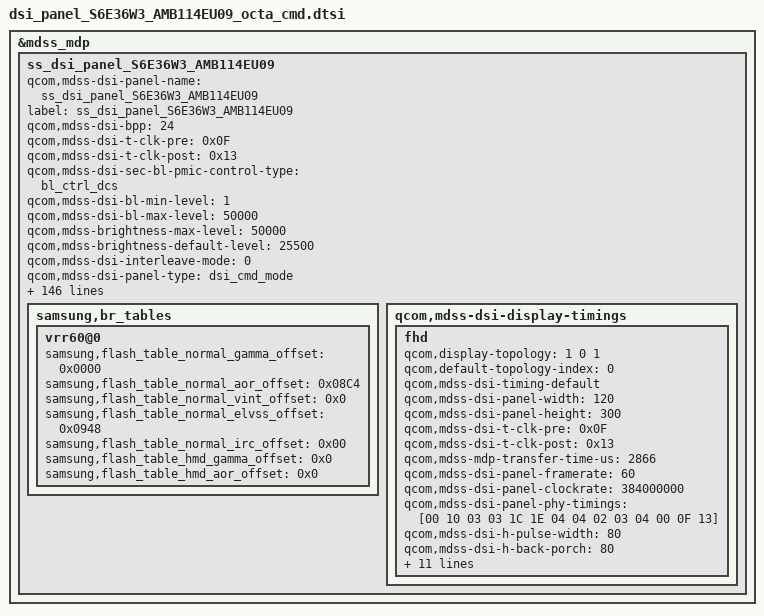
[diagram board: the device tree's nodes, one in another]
/* Copyright (c) 2013-2014, The Linux Foundation. All rights reserved.
 *
 * This program is free software; you can redistribute it and/or modify
 * it under the terms of the GNU General Public License version 2 and
 * only version 2 as published by the Free Software Foundation.
 *
 * This program is distributed in the hope that it will be useful,
 * but WITHOUT ANY WARRANTY; without even the implied warranty of
 * MERCHANTABILITY or FITNESS FOR A PARTICULAR PURPOSE.  See the
 * GNU General Public License for more details.
 */

/*---------------------------------------------------------------------------
 * This file is autogenerated file using gcdb parser. Please do not edit it.
 * Update input XML file to add a new entry or update variable in this file
 * VERSION = "1.0"
 *---------------------------------------------------------------------------*/
&mdss_mdp {
	ss_dsi_panel_S6E36W3_AMB114EU09: ss_dsi_panel_S6E36W3_AMB114EU09 {
		qcom,mdss-dsi-panel-name = "ss_dsi_panel_S6E36W3_AMB114EU09";
		label = "ss_dsi_panel_S6E36W3_AMB114EU09";
		qcom,mdss-dsi-bpp = <24>;
		qcom,mdss-dsi-t-clk-pre = <0x0F>;
		qcom,mdss-dsi-t-clk-post = <0x13>;
		qcom,mdss-dsi-sec-bl-pmic-control-type = "bl_ctrl_dcs";

		qcom,mdss-dsi-bl-min-level = <1>;
		qcom,mdss-dsi-bl-max-level = <50000>;
		qcom,mdss-brightness-max-level = <50000>;
		qcom,mdss-brightness-default-level = <25500>;

		qcom,mdss-dsi-interleave-mode = <0>;
		qcom,mdss-dsi-panel-type = "dsi_cmd_mode";

		qcom,mdss-dsi-te-check-enable;
		qcom,mdss-dsi-te-using-te-pin;
		qcom,mdss-dsi-te-pin-select = <1>;

		qcom,mdss-dsi-te-dcs-command = <1>;
		qcom,mdss-dsi-wr-mem-start = <0x2C>;
		qcom,mdss-dsi-wr-mem-continue = <0x3C>;

		/* CMD mode panel doesn't need below stuff */
		qcom,mdss-dsi-h-sync-pulse= <0>;
		/*qcom,mdss-dsi-hfp-power-mode=*/
		/*qcom,mdss-dsi-hbp-power-mode=*/
		/*qcom,mdss-dsi-hsa-power-mode=*/
		/*qcom,mdss-dsi-last-line-interleave=*/
		qcom,mdss-dsi-bllp-eof-power-mode;
		qcom,mdss-dsi-bllp-power-mode;
		qcom,mdss-dsi-traffic-mode= "burst_mode";

		qcom,mdss-dsi-pixel-packing = "loose";

		qcom,mdss-dsi-virtual-channel-id = <0>;
		qcom,mdss-dsi-color-order = "rgb_swap_rgb";
		qcom,mdss-dsi-lane-0-state;
		samsung,num_of_data_lanes = <1>;

		qcom,mdss-dsi-stream = <0>;
		qcom,mdss-dsi-mdp-trigger = "none";
		qcom,mdss-dsi-dma-trigger = "trigger_sw";

		qcom,mdss-dsi-off-command-state = "dsi_hs_mode";

		qcom,mdss-pan-physical-width-dimension = <10>;	/* 9.93mm */
		qcom,mdss-pan-physical-height-dimension = <25>;	/* 25.11mm */

		qcom,mdss-dsi-reset-sequence = <1 5>;

		qcom,mdss-dsi-rx-eot-ignore;
		qcom,mdss-dsi-tx-eot-append;
		qcom,ulps-enabled;

		/* HDR Setting */
		qcom,mdss-dsi-panel-hdr-enabled;
		qcom,mdss-dsi-panel-hdr-color-primaries = <15635 16450 34000 16000 13250 34500 7500 3000>;
		qcom,mdss-dsi-panel-peak-brightness = <4000000>;
		qcom,mdss-dsi-panel-average-brightness = <1200000>;
		qcom,mdss-dsi-panel-blackness-level = <5>;		

		/*qcom,mdss-dsi-panel-status-command=*/
		/*qcom,mdss-dsi-panel-status-command-mode="dsi_lp_mode";*/
		/*qcom,esd-check-enabled;*/
		qcom,mdss-dsi-panel-status-check-mode="irq_check";
		/*qcom,mdss-dsi-panel-status-value = <1>;*/
		qcom,mdss-dsi-panel-status-irq-trigger1="falling";

		/*qcom,dynamic-mode-switch-enabled;*/
		/*qcom,dynamic-mode-switch-type = "dynamic-resolution-switch-immediate";*/
		/*qcom,dynamic-mode-switch-enabled*/
		/*qcom,video-to-cmd-mode-switch-commands=*/
		/*qcom,cmd-to-video-mode-switch-commands=*/

		/*qcom,adjust-timer-wakeup-ms = <1>;*/

/*
 * ************************************************************************************************************************************
 *
 *
 *			for log debug
 *
 *
 * ************************************************************************************************************************************
 */
		samsung,ldi_log_disable_tx_cmds_revA = [
			29 01 00 00 00 00 02 F2 00			/* DDI Log Disable */
		];

		samsung,ldi_log_enable_tx_cmds_revA = [
			29 01 00 00 00 00 02 F2 13			/* DDI Log Enable */
		];

		samsung,ldi_log_rx_cmds_revA		= [06 01 00 00 00 00 01 9C 80 00];

/*
 * ************************************************************************************************************************************
 *
 *
 *			Below  parameters are samsung dependent thigs
 *
 *
 * ************************************************************************************************************************************
 */
		samsung,support_panel_max = <1>;
/*		samsung,panel-lpm-enable;*/
		samsung,support_factory_panel_swap;
		samsung,support_irc;
/*		samsung,support_pac;*/
/*		samsung,support_poc_driver;*/
/*		samsung,support_gpara;*/
		samsung,multi_to_one_support;
		samsung,support_window_color;
		/*
		* ************************************************************************************************************************
		*  Tx
		* ************************************************************************************************************************
		*/

		samsung,display_on_tx_cmds_revA = [
			05 01 00 00 00 00 01 29
		];

		samsung,display_off_tx_cmds_revA = [
			05 01 00 00 00 00 01 28
		];

		samsung,level1_key_enable_tx_cmds_revA = [
			29 01 00 00 00 00 03 F0 5A 5A
		];
		samsung,level1_key_disable_tx_cmds_revA = [
			29 01 00 00 00 00 03 F0 A5 A5
		];
		samsung,level2_key_enable_tx_cmds_revA = [
			29 00 00 00 00 00 03 F0 5A 5A
			29 01 00 00 00 00 03 FC 5A 5A
		];
		samsung,level2_key_disable_tx_cmds_revA = [
			29 00 00 00 00 00 03 F0 A5 A5
			29 01 00 00 00 00 03 FC A5 A5
		];

		/* BRIGHTNESS_MAX_PACKET = 50 */
		samsung,brightness_tx_cmds_revA = [
			39 01 00 00 00 00 01 00
			39 01 00 00 00 00 01 00
			39 01 00 00 00 00 01 00
			39 01 00 00 00 00 01 00
			39 01 00 00 00 00 01 00
			39 01 00 00 00 00 01 00
			39 01 00 00 00 00 01 00
			39 01 00 00 00 00 01 00
			39 01 00 00 00 00 01 00
			39 01 00 00 00 00 01 00
			39 01 00 00 00 00 01 00
			39 01 00 00 00 00 01 00
			39 01 00 00 00 00 01 00
			39 01 00 00 00 00 01 00
			39 01 00 00 00 00 01 00
			39 01 00 00 00 00 01 00
			39 01 00 00 00 00 01 00
			39 01 00 00 00 00 01 00
			39 01 00 00 00 00 01 00
			39 01 00 00 00 00 01 00
			39 01 00 00 00 00 01 00
			39 01 00 00 00 00 01 00
			39 01 00 00 00 00 01 00
			39 01 00 00 00 00 01 00
			39 01 00 00 00 00 01 00
			39 01 00 00 00 00 01 00
			39 01 00 00 00 00 01 00
			39 01 00 00 00 00 01 00
			39 01 00 00 00 00 01 00
			39 01 00 00 00 00 01 00
			39 01 00 00 00 00 01 00
			39 01 00 00 00 00 01 00
			39 01 00 00 00 00 01 00
			39 01 00 00 00 00 01 00
			39 01 00 00 00 00 01 00
			39 01 00 00 00 00 01 00
			39 01 00 00 00 00 01 00
			39 01 00 00 00 00 01 00
			39 01 00 00 00 00 01 00
			39 01 00 00 00 00 01 00
			39 01 00 00 00 00 01 00
			39 01 00 00 00 00 01 00
			39 01 00 00 00 00 01 00
			39 01 00 00 00 00 01 00
			39 01 00 00 00 00 01 00
			39 01 00 00 00 00 01 00
			39 01 00 00 00 00 01 00
			39 01 00 00 00 00 01 00
			39 01 00 00 00 00 01 00
			39 01 00 00 00 00 01 00
		];

		samsung,mdnie_tx_cmds_revA = [
			39 01 00 00 00 00 00 00 00
		];

		samsung,packet_size_tx_cmds_revA = [
			37 01 00 00 00 00 02 07 00
		];

		/*
		 * First parameters can be changed
		 * by function of samsung_nv_read()
		 * because of that means offset of
		 * read position
		 */
		samsung,reg_read_pos_tx_cmds_revA = [
			15 01 00 00 00 00 02 B0 00
		];

		/*
		 * ************************************************************************************************************************
		 *	 06 01 00 00 00 00 01 c8 07 21
		 *	READ 0xC8 SIZE 0x07 OFFSET 0x21
		 * ************************************************************************************************************************
		 */
		samsung,smart_dimming_mtp_rx_cmds_revA = [ 06 01 00 00 00 00 01 c8 24 00]; /* read C8 36para */
		/* the last byte in all read commands will represent READ LENGH */
		samsung,manufacture_id0_rx_cmds_revA = [ 06 01 00 00 00 00 01 da 01 00];
		samsung,manufacture_id1_rx_cmds_revA = [ 06 01 00 00 00 00 01 db 01 00];
		samsung,manufacture_id2_rx_cmds_revA = [ 06 01 00 00 00 00 01 dc 01 00];

		samsung,manufacture_date_rx_cmds_revA = [ 06 01 00 00 00 00 01 A1 04 04];	/* read A1 5~8th */
		samsung,ddi_id_rx_cmds_revA = [ 06 01 00 00 00 00 01 d6 05 00];	/* read D6 1~5th */
		samsung,cell_id_rx_cmds_revA = [ 06 01 00 00 00 00 01 A1 07 04]; /* read A1 5th~11th */
		samsung,octa_id_rx_cmds_revA = [06 01 00 00 00 00 01 C9 14 01];  // read C9 2th~21th
		samsung,mtp_read_sysfs_rx_cmds_revA = [ 06 01 00 00 00 00 01 01 01 01];
		samsung,mtp_write_sysfs_tx_cmds_revA = [
			29 01 00 00 00 00 0E 00
						00 00 00 00 00 00 00 00 00 00
						00 00 00
		];
		samsung,mdnie_read_rx_cmds_revA	= [ 06 01 00 00 00 00 01 A1 04 00];

		samsung,ldi_debug0_rx_cmds_revA		= [06 01 00 00 00 00 01 0A 01 00];
		samsung,ldi_debug1_rx_cmds_revA		= [06 01 00 00 00 00 01 ED 01 00];
	/*	samsung,ldi_debug2_rx_cmds_revA		= [06 01 00 00 00 00 01 EE 01 00]; */
	/*	samsung,ldi_debug3_rx_cmds_revA		= [06 01 00 00 00 00 01 0E 01 00]; */
	/*	samsung,ldi_debug4_rx_cmds_revA		= [06 01 00 00 00 00 01 05 01 00]; */
	/*	samsung,ldi_debug5_rx_cmds_revA		= [06 01 00 00 00 00 01 0F 01 00]; */

		/* *************************************************************
		 *  SELF DISPLAY
		 * *************************************************************
		 */
		samsung,support_self_display;
		ss,self_display = <&self_display_6W3_dtsi>;
		/*
		 * ************************************************************************************************************************
		 *	 COMMON CMD LIST
		 * ************************************************************************************************************************
		 */

		samsung,gamma_tx_cmds_revA = [
		29 01 00 00 00 00 23 CA				/* 1) Gamma 2.2 Setting */
						07 00 00 00			/* V255 R,G,B */
						80 80 80			/* V203 R,G,B */
						80 80 80			/* V151 R,G,B */
						80 80 80			/* V87 R,G,B */
						80 80 80			/* V51 R,G,B */
						80 80 80			/* V35 R,G,B */
						80 80 80			/* V23 R,G,B */
						80 80 80			/* V11 R,G,B */
						80 80 80			/*  V7 R,G,B */
						80 80 80			/*  V1 R,G,B */
						00 00 00			/*  V0 R,G,B & VT G,R,B*/

			29 01 00 00 00 00 02 F7 03	/* Gamma, LTPS(AID) update */

			29 01 00 00 00 00 3C		/* dummy for single transmission more 100ns delay */
			00 00 00 00 00 00 00 00 00 00
			00 00 00 00 00 00 00 00 00 00
			00 00 00 00 00 00 00 00 00 00
			00 00 00 00 00 00 00 00 00 00
			00 00 00 00 00 00 00 00 00 00
			00 00 00 00 00 00 00 00 00 00
		];

		/*
		* ************************************************************************************************************************
		*  HBM
		* ************************************************************************************************************************
		*/

		samsung,enter_hbm_ce_lux = <10000>;
		samsung,hbm_etc_tx_cmds_revA = [
			29 00 00 00 00 00 03 F0 5A 5A		/* TEST KEY Enable */
			29 00 00 00 00 00 04 B5 19 DC 0A	/* MPS/ELVSS Setting */ /* TBD */
			29 00 00 00 00 00 02 B3 21			/* HBM ACL ON */
			29 00 00 00 00 00 02 55 00			/* ACL OFF */
			29 00 00 00 00 00 04 B1 00 20 20	/* AID Setting 1000nit*/
			29 00 00 00 00 00 02 53 C0			/* HBM ON */
			29 00 00 00 00 00 02 F7 03			/* Gamma & AID update */
			29 01 00 00 00 00 03 F0 5A 5A		/* TEST KEY Disable */
		];

		samsung,hbm_off_tx_cmds_revA = [
			29 01 00 00 00 00 02 53 00			/* HBM off */
		];

		/* *************************************************************
		 * TEST MODE
		 * **************************************************************
		 */
		samsung,mcd_on_tx_cmds_revA = [
			29 01 00 00 00 00 03 F0 5A 5A
			29 01 00 00 64 00 49 CB
				20 01 01 01 40 01 01 23
				34 50 12 00 00 09 02 00
				00 00 00 00 00 6D 60 00
				00 00 00 07 00 00 00 00
				00 02 C4 02 09 01 02 0C
				0C 0C 0C 0C 0C D4 0F 10
				0D 84 05 C2 0B 0B 0B EB
				EB CB D3 D4 CF 50 CD C4
				C5 E2 EB 0B 0B 0B 0B 0B

			29 01 00 00 00 00 02 F7 02
			29 01 00 00 00 00 08 F2
				34 15 2C 60 30 96 00

			29 01 00 00 00 00 03 F0 A5 A5
		];

		samsung,mcd_off_tx_cmds_revA = [
			29 01 00 00 00 00 03 F0 5A 5A
			29 01 00 00 64 00 49 CB
				20 01 01 01 40 01 01 33
				34 50 12 00 00 09 04 00
				00 00 00 00 00 6D 60 00
				00 00 00 07 00 00 00 00
				00 02 C4 00 00 01 02 0C
				0C 0C 0C 0C 0C D4 0F 10
				0D 84 05 C2 16 17 18 F9
				FA DB D3 D4 CF 50 CD C4
				C5 E2 F6 17 18 19 1A 1B

			29 01 00 00 00 00 02 F7 02
			29 01 00 00 00 00 08 F2
				34 15 2C 60 30 96 2B
			
			29 01 00 00 00 00 03 F0 A5 A5
		];
		
		/*
		 * ************************************************************************************************************************
		 * ACL command list and mappings
		 * ************************************************************************************************************************
		 */

		samsung,acl_on_tx_cmds_revA = [
			29 01 00 00 00 00 02 55 02	/* ACL ON */
		];


		samsung,acl_off_tx_cmds_revA = [
			29 01 00 00 00 00 02 55 00	 /* ACL OFF */
		];

		/* bl_level , Index in acl command list */
		samsung,acl_map_table_revA =  <
			10	1		11	1
			12	1		13	1		14	1		15	1		16	1
			17	1		19	1		20	1		21	1		22	1
			24	1		25	1		27	1		29	1		30	1
			32	1		34	1		37	1		39	1		41	1
			44	1		47	1		50	1		53	1		56	1
			60	1		64	1		68	1		72	1		77	1
			82	1		87	1		93	1		98	1		105	1
			111	1		119	1		126	1		134	1		143	1
			152	1		162	1		172	1		183	1		195	1
			207	1		220	1		234	1		249	1		265	1
			282	1		300	1		316	1		333	1		350	1
			357	1		365	1		372	1		380	1		387	1
			395	1		403	1		412	1		420	1
		>;
		/*
		* ************************************************************************************************************************
		* ELVSS command list and mappings
		* ************************************************************************************************************************
		*/

		/* TSET MPS_CON ELVSS_Dim_offset */
		samsung,elvss_tx_cmds_revA = [
			29 01 00 00 00 00 04 B5 19 DC 0A /* 0  420CD ~ 395CD */
			29 01 00 00 00 00 04 B5 19 DC 0B /* 1  387CD ~ 333CD */
			29 01 00 00 00 00 04 B5 19 DC 0C /* 2  316CD ~ 282CD */
			29 01 00 00 00 00 04 B5 19 DC 0D /* 3  265CD ~ 249CD*/
			29 01 00 00 00 00 04 B5 19 DC 0E /* 4  234CD ~ 152CD*/
			29 01 00 00 00 00 04 B5 19 DC 0F /* 5  143CD ~ 105CD */
			29 01 00 00 00 00 04 B5 19 DC 10 /* 6  98CD ~ 10CD */
		];

		/* bl_level, Index in elvss command list */
		samsung,smart_acl_elvss_map_table_revA = <
			10	6	11	6
			12	6	13	6	14	6	15	6	16	6
			17	6	19	6	20	6	21	6	22	6
			24	6	25	6	27	6	29	6	30	6
			32	6	34	6	37	6	39	6	41	6
			44	6	47	6	50	6	53	6	56	6
			60	6	64	6	68	6	72	6	77	6
			82	6	87	6	93	6	98	6	105	5
			111	5	119	5	126	5	134	5	143	5
			152	4	162	4	172	4	183	4	195	4
			207	4	220	4	234	4	249	3	265	3
			282	2	300	2	316	2	333	1	350	1
			357	1	365	1	372	1	380	1	387	1
			395	1	403	1	412	0	420	0
		>;
		/* *************************************************************
		 * AID command list and mappings
		 * **************************************************************
		 */
		/* Original aid table for all steps. */
		samsung,aid_subdivision_tx_cmds_revA = [
			29 01 00 00 00 00 03 B1	01 23	/*	10 	*/
			29 01 00 00 00 00 03 B1	01 21	/*	11 	*/
			29 01 00 00 00 00 03 B1	01 1C	/*	12 	*/
			29 01 00 00 00 00 03 B1	01 1C	/*	13 	*/
			29 01 00 00 00 00 03 B1	01 1A	/*	14 	*/
			29 01 00 00 00 00 03 B1	01 19	/*	15 	*/
			29 01 00 00 00 00 03 B1	01 13	/*	16 	*/
			29 01 00 00 00 00 03 B1	01 12	/*	17 	*/
			29 01 00 00 00 00 03 B1	01 0B	/*	19 	*/
			29 01 00 00 00 00 03 B1	01 0A	/*	20 	*/
			29 01 00 00 00 00 03 B1	01 05	/*	21 	*/
			29 01 00 00 00 00 03 B1	01 03	/*	22 	*/
			29 01 00 00 00 00 03 B1	00 FC	/*	24 	*/
			29 01 00 00 00 00 03 B1	00 FB	/*	25 	*/
			29 01 00 00 00 00 03 B1	00 F4	/*	27 	*/
			29 01 00 00 00 00 03 B1	00 F1	/*	29 	*/
			29 01 00 00 00 00 03 B1	00 EC	/*	30 	*/
			29 01 00 00 00 00 03 B1	00 E9	/*	32 	*/
			29 01 00 00 00 00 03 B1	00 E2	/*	34 	*/
			29 01 00 00 00 00 03 B1	00 DA	/*	37 	*/
			29 01 00 00 00 00 03 B1	00 D3	/*	39 	*/
			29 01 00 00 00 00 03 B1	00 CF	/*	41 	*/
			29 01 00 00 00 00 03 B1	00 C8	/*	44 	*/
			29 01 00 00 00 00 03 B1	00 BE	/*	47 	*/
			29 01 00 00 00 00 03 B1	00 B4	/*	50 	*/
			29 01 00 00 00 00 03 B1	00 AC	/*	53 	*/
			29 01 00 00 00 00 03 B1	00 A4	/*	56 	*/
			29 01 00 00 00 00 03 B1	00 9A	/*	60 	*/
			29 01 00 00 00 00 03 B1	00 8B	/*	64 	*/
			29 01 00 00 00 00 03 B1	00 84	/*	68 	*/
			29 01 00 00 00 00 03 B1	00 84	/*	72 	*/
			29 01 00 00 00 00 03 B1	00 84	/*	77 	*/
			29 01 00 00 00 00 03 B1	00 84	/*	82 	*/
			29 01 00 00 00 00 03 B1	00 84	/*	87 	*/
			29 01 00 00 00 00 03 B1	00 84	/*	93 	*/
			29 01 00 00 00 00 03 B1	00 84	/*	98 	*/
			29 01 00 00 00 00 03 B1	00 84	/*	105 	*/
			29 01 00 00 00 00 03 B1	00 84	/*	111 	*/
			29 01 00 00 00 00 03 B1	00 84	/*	119 	*/
			29 01 00 00 00 00 03 B1	00 84	/*	126 	*/
			29 01 00 00 00 00 03 B1	00 84	/*	134 	*/
			29 01 00 00 00 00 03 B1	00 84	/*	143 	*/
			29 01 00 00 00 00 03 B1	00 84	/*	152 	*/
			29 01 00 00 00 00 03 B1	00 84	/*	162 	*/
			29 01 00 00 00 00 03 B1	00 84	/*	172 	*/
			29 01 00 00 00 00 03 B1	00 82	/*	183 	*/
			29 01 00 00 00 00 03 B1	00 73	/*	195 	*/
			29 01 00 00 00 00 03 B1	00 63	/*	207 	*/
			29 01 00 00 00 00 03 B1	00 53	/*	220 	*/
			29 01 00 00 00 00 03 B1	00 43	/*	234 	*/
			29 01 00 00 00 00 03 B1	00 3D	/*	249 	*/
			29 01 00 00 00 00 03 B1	00 3D	/*	265 	*/
			29 01 00 00 00 00 03 B1	00 3D	/*	282 	*/
			29 01 00 00 00 00 03 B1	00 3D	/*	300 	*/
			29 01 00 00 00 00 03 B1	00 3D	/*	316 	*/
			29 01 00 00 00 00 03 B1	00 3D	/*	333 	*/
			29 01 00 00 00 00 03 B1	00 3D	/*	350 	*/
			29 01 00 00 00 00 03 B1	00 3D	/*	357 	*/
			29 01 00 00 00 00 03 B1	00 3B	/*	365 	*/
			29 01 00 00 00 00 03 B1	00 34	/*	372 	*/
			29 01 00 00 00 00 03 B1	00 2C	/*	380 	*/
			29 01 00 00 00 00 03 B1	00 27	/*	387 	*/
			29 01 00 00 00 00 03 B1	00 23	/*	395 	*/
			29 01 00 00 00 00 03 B1	00 20	/*	403 	*/
			29 01 00 00 00 00 03 B1	00 20	/*	412 	*/
			29 01 00 00 00 00 03 B1	00 20	/*	420 	*/
		];
		/*
		 * ************************************************************************************************************************
		 * candela to index mappings
		 * ************************************************************************************************************************
		 */
		samsung,candela_map_table_revA = <
		/* <scaled idx> <idx>  <from>  <end> <cd> <interpolation cd>*/
			0	0	4099	10
			1	4100	4299	11
			2	4300	4499	12
			3	4500	4699	13
			4	4700	4899	14
			5	4900	5099	15
			6	5100	5299	16
			7	5300	5499	17
			8	5500	5699	19
			9	5700	5799	20
			10	5800	5999	21
			11	6000	6199	22
			12	6200	6399	24
			13	6400	6599	25
			14	6600	6799	27
			15	6800	6999	29
			16	7000	7099	30
			17	7100	7299	32
			18	7300	7499	34
			19	7500	7699	37
			20	7700	7899	39
			21	7900	8099	41
			22	8100	8299	44
			23	8300	8499	47
			24	8500	8699	50
			25	8700	8899	53
			26	8900	9099	56
			27	9100	9299	60
			28	9300	9499	64
			29	9500	9699	68
			30	9700	9899	72
			31	9900	10099	77
			32	10100	10299	82
			33	10300	10499	87
			34	10500	10699	93
			35	10700	10899	98
			36	10900	11099	105
			37	11100	11299	111
			38	11300	11499	119
			39	11500	11699	126
			40	11700	11899	134
			41	11900	12099	143
			42	12100	12399	152
			43	12400	12699	162
			44	12700	12799	172
			45	12800	12899	183
			46	12900	13599	195
			47	13600	14299	207
			48	14300	14999	220
			49	15000	15799	234
			50	15800	16599	249
			51	16600	17499	265
			52	17500	18399	282
			53	18400	19399	300
			54	19400	20199	316
			55	20200	21099	333
			56	21100	21999	350
			57	22000	22399	357
			58	22400	22799	365
			59	22800	23099	372
			60	23100	23499	380
			61	23500	23899	387
			62	23900	24299	395
			63	24300	24699	403
			64	24700	25099	412
			65	25100	25500	420
		>;
		/* GRAY/ BRONZE use same table_revA 50/183/300/420/670/1000 */
		samsung,multi_to_one_candela_map_table_revA = <
		/* <idx>  <from>  <end> <cd> */
			24	0	2399	50
			45	2400	4899	183
			53	4900	7299	300
			65	7300	9599	420
 		>;
		samsung,hbm_candela_map_table_revA = <
			0	9600	11999	670	5
			1	12000	50000	1000	6
		>;

		/* WHITE uses table_revK 32/119/207/282/440/666 */
		samsung,multi_to_one_candela_map_table_revK = <
		/* <idx>  <from>  <end> <cd> */
			17	0	2399	32			/* BLOOMX_TODO : need to modify proper idx & cd values for WHITE */
			38	2400	4899	119
			47	4900	7299	207
			52	7300	9599	282
 		>;

		samsung,hbm_candela_map_table_revK = <
			0	9600	11999	440	5		/* BLOOMX_TODO : need to modify proper just cd value for WHITE */
			1	12000	50000	666	6
		>;

		/*
		* ************************************************************************************************************************
		*  VINT
		* ************************************************************************************************************************
		*/

		/*
		* ************************************************************************************************************************
		* Self Display Operation (ENABLE)
		* ************************************************************************************************************************
		*/

		samsung,self_dispaly_on_revA = [
			29 01 00 00 00 00 03 F0 5A 5A	/* TEST KEY Enable */
			29 01 00 00 00 00 07 76
								08 10 84 38 08
								AC
			29 01 00 00 00 00 03 F0 A5 A5	/* TEST KEY Disable */
		];

		samsung,self_dispaly_off_revA = [
			29 01 00 00 00 00 03 F0 5A 5A	/* TEST KEY Enable */
			29 01 00 00 00 00 04 76
								08 10 00
			29 01 00 00 00 00 03 F0 A5 A5	/* TEST KEY Disable */
		];

		/*
		* ************************************************************************************************************************
		* Self Display Operation (SELF MASK)
		* ************************************************************************************************************************
		*/

		samsung,self_mask_mem_setting_revA = [
			29 01 00 00 00 00 03 F0 5A 5A	/* TEST KEY Enable */
			29 01 00 00 00 00 02 7A 00		/* SM_MASK_EN(0)   */
			29 01 00 00 00 00 02 75 10		/* MA_SEL(1), IC_SEL, VI_SEL, DC_SEL, AC_SEL */
			/* image data (4C,5C) ... */
			29 01 00 00 00 00 03 F0 A5 A5	/* TEST KEY Disable */
		];

		samsung,self_mask_on_revA = [
			29 01 00 00 00 00 03 F0 5A 5A	/* TEST KEY Enable */
			29 01 00 00 00 00 10 7A
								01 00 00 00 3B
								08 70 08 AB 08
								10 00 00 00 00
			29 01 00 00 00 00 03 F0 A5 A5	/* TEST KEY Disable */
		];

		samsung,self_mask_off_revA = [
			29 01 00 00 00 00 03 F0 5A 5A	/* TEST KEY Enable  */
			29 01 00 00 00 00 02 7A 00		/* SM_MASK_EN(0)	*/
			29 01 00 00 00 00 03 F0 A5 A5	/* TEST KEY Disable */
		];

#if 0
		/*
		* ************************************************************************************************************************
		* Self Display Operation (SELF MOVE)
		* ************************************************************************************************************************
		*/

		samsung,self_move_small_jump_on_revA = [
			29 01 00 00 00 00 03 F0 5A 5A	/* TEST KEY Enable */
			29 01 00 00 00 00 02 B0 33
			29 01 00 00 00 00 62 7D
								00 00 00 00 00
								00 00 33 33 33
								33 33 33 33 33
								33 33 33 33 33
								33 33 33 33 33
								33 33 33 33 33
								33 33 33 33 33
								33 33 33 33 33
								33 33 33 33 33
								33 33 33 33 33
								33 33 33 33 33
								33 33 33 33 33
								33 33 33 33 33
								33 11 11 11 11
								11 11 11 11 11
								11 11 11 11 11
								11 11 11 11 11
								11 11 11 11 11
								11 11 11 11 11
								11 90
			29 01 00 00 00 00 03 F0 A5 A5	/* TEST KEY Disable */
		];

		samsung,self_move_mid_big_jump_on_revA = [
			29 01 00 00 00 00 03 F0 5A 5A	/* TEST KEY Enable */
		/*	29 01 00 00 00 00 02 B0 33 */
			29 01 00 00 00 00 62 7D
								00 00 00 00 00
								00 00 33 33 33
								33 33 33 33 33
								33 33 33 33 33
								33 33 33 33 33
								33 33 33 33 33
								33 33 33 33 33
								33 33 33 33 33
								33 33 33 33 33
								33 33 33 33 33
								33 33 33 33 33
								33 33 33 33 33
								33 33 33 33 33
								33 11 11 11 11
								11 11 11 11 11
								11 11 11 11 11
								11 11 11 11 11
								11 11 11 11 11
								11 11 11 11 11
								11 90
			29 01 00 00 00 00 03 F0 A5 A5	/* TEST KEY Disable */
		];

		samsung,self_move_off_revA = [
			29 01 00 00 00 00 03 F0 5A 5A	/* TEST KEY Enable  */
			29 01 00 00 00 00 03 7D 00 03
			29 01 00 00 00 00 03 F0 A5 A5	/* TEST KEY Disable */
		];

		samsung,self_move_2c_sync_off_revA = [
			29 01 00 00 00 00 03 F0 5A 5A	/* TEST KEY Enable */
			29 01 00 00 00 00 02 7C 01
			29 01 00 00 00 00 03 F0 A5 A5	/* TEST KEY Disable */
		];

		/*
		* ************************************************************************************************************************
		* Self Display Operation (SELF ICON)
		* ************************************************************************************************************************
		*/

		samsung,self_icon_mem_setting_revA = [
			29 01 00 00 00 00 03 7C 00 00
			29 01 00 00 00 00 02 75 08		/* MA_SEL, IC_SEL(1), VI_SEL, DC_SEL, AC_SEL */
			/* image data (4C,5C) ... */
		];

		samsung,self_icon_on_grid_on_revA = [
			29 01 00 00 00 00 03 F0 5A 5A	/* TEST KEY Enable */
			29 01 00 00 00 00 16 7C
								00 11 02 00 02
								00 01 00 01 00
								70 11 00 00 00
								00 04 38 08 AC
								1E
			29 01 00 00 00 00 03 F0 A5 A5	/* TEST KEY Disable */
		];

		samsung,self_icon_on_grid_off_revA = [
			29 01 00 00 00 00 03 F0 5A 5A	/* TEST KEY Enable */
			29 01 00 00 00 00 0B 7C
								00 01 02 00 02
								00 01 00 01 00
			29 01 00 00 00 00 03 F0 A5 A5	/* TEST KEY Disable */
		];

		samsung,self_icon_off_grid_on_revA = [
			29 01 00 00 00 00 03 F0 5A 5A	/* TEST KEY Enable */
			29 01 00 00 00 00 16 7C
								00 10 00 00 00
								00 00 00 00 00
								70 11 00 00 00
								00 04 38 08 AC
								1E
			29 01 00 00 00 00 03 F0 A5 A5	/* TEST KEY Disable */
		];

		samsung,self_icon_off_grid_off_revA = [
			29 01 00 00 00 00 03 F0 5A 5A	/* TEST KEY Enable */
			29 01 00 00 00 00 03 7C
								00 00
			29 01 00 00 00 00 03 F0 A5 A5	/* TEST KEY Disable */
		];

		samsung,self_brightness_icon_on_revA = [
			29 01 00 00 00 00 03 F0 5A 5A	/* TEST KEY Enable */
			29 01 00 00 00 00 16 7C
								00 11 02 00 02
								00 01 00 01 00
								70 1F 00 00 00
								00 04 38 08 AC
								1E
			29 01 00 00 00 00 03 F0 A5 A5	/* TEST KEY Disable */
		];

		samsung,self_brightness_icon_off_revA = [
			29 01 00 00 00 00 03 F0 5A 5A	/* TEST KEY Enable */
			29 01 00 00 00 00 16 7C
								00 10 00 00 00
								00 00 00 00 00
								70 1F 00 00 00
								00 04 38 08 AC
								1E
			29 01 00 00 00 00 03 F0 A5 A5	/* TEST KEY Disable */
		];

		samsung,self_icon_grid_2c_sync_off_revA = [
			29 01 00 00 00 00 03 F0 5A 5A	/* TEST KEY Enable */
			29 01 00 00 00 00 02 7C 03
			29 01 00 00 00 00 03 F0 A5 A5	/* TEST KEY Disable */
		];


		/*
		* ************************************************************************************************************************
		* Self Display Operation (SELF ALALOG CLOCK)
		* ************************************************************************************************************************
		*/

		samsung,self_aclock_sidemem_setting_revA = [
			29 01 00 00 00 00 03 7C 00 00
			29 01 00 00 00 00 02 75 01
			/* image data (4C,5C) ... */
		];

		samsung,self_aclock_on_revA = [
			29 01 00 00 00 00 03 F0 5A 5A	/* TEST KEY Enable */
			29 01 00 00 00 00 16 77
								00 07 00 0A 0A
								1D 00 03 01 02
								00 02 00 00 00
								B4 13 B4 13 B4
								13
			29 01 00 00 00 00 03 F0 A5 A5	/* TEST KEY Disable */
		];

		samsung,self_aclock_time_update_revA = [
			29 01 00 00 00 00 03 F0 5A 5A	/* TEST KEY Enable */
			29 01 00 00 00 00 08 77
								00 07 00 05 03
								20 00
			29 01 00 00 00 00 02 78 01		/* SC_TIME_UPDATE */
			29 01 00 00 00 00 03 F0 A5 A5	/* TEST KEY Disable */
		];

		samsung,self_aclock_rotation_revA = [
			29 01 00 00 00 00 03 F0 5A 5A	/* TEST KEY Enable */
			29 01 00 00 00 00 0F 77
								00 07 00 00 00
								00 00 03 01 02
								00 02 00 D1
			29 01 00 00 00 00 03 F0 A5 A5	/* TEST KEY Disable */
		];

		samsung,self_aclock_off_revA = [
			29 01 00 00 00 00 03 F0 5A 5A	/* TEST KEY Enable */
			29 01 00 00 00 00 03 77 00 00
			29 01 00 00 00 00 03 F0 A5 A5	/* TEST KEY Disable */
		];

		samsung,self_clock_2c_sync_off_revA = [
			29 01 00 00 00 00 03 F0 5A 5A	/* TEST KEY Enable */
			29 01 00 00 00 00 02 77 01
			29 01 00 00 00 00 03 F0 A5 A5	/* TEST KEY Disable */
		];

		/*
		* ************************************************************************************************************************
		* Self Display Operation (SELF DIGITAL CLOCK)
		* ************************************************************************************************************************
		*/

		samsung,self_dclock_sidemem_setting_revA = [
			29 01 00 00 00 00 03 77 00 00
			29 01 00 00 00 00 02 75 02
			/* image data (4C,5C) ... */
		];

		samsung,self_dclock_on_revA = [
			29 01 00 00 00 00 03 F0 5A 5A	/* TEST KEY Enable */
			29 01 00 00 00 00 2A 77
								00 36 05 0A 03
								00 00 03 00 00
								00 00 00 00 00
								00 00 00 00 00
								00 01 2C 01 90
								01 F4 01 90 01
								2C 02 F4 02 F4
								01 F4 00 C8 01
								64
			29 01 00 00 00 00 03 F0 A5 A5	/* TEST KEY Disable */
		];

		samsung,self_dclock_dlinking_on_revA = [
			29 01 00 00 00 00 03 F0 5A 5A	/* TEST KEY Enable */
			29 01 00 00 00 00 1B 79
								00 C0 00 00 00
								00 57 01 0A 0A
								00 FF 00 00 FF
								00 02 08 06 72
								02 08 06 D6 1D
								1D
			29 01 00 00 00 00 03 F0 A5 A5	/* TEST KEY Disable */
		];

		samsung,self_dclock_time_update_revA = [
			29 01 00 00 00 00 03 F0 5A 5A	/* TEST KEY Enable */
			29 01 00 00 00 00 08 77
								00 36 05 03 1A
								20 00
			29 01 00 00 00 00 02 78 01		/* SC_TIME_UPDATE */
			29 01 00 00 00 00 03 F0 A5 A5	/* TEST KEY Disable */
		];

		samsung,self_dclock_off_revA = [
			29 01 00 00 00 00 03 F0 5A 5A	/* TEST KEY Enable */
			29 01 00 00 00 00 03 77 00 00
			29 01 00 00 00 00 03 F0 A5 A5	/* TEST KEY Disable */
		];

		samsung,self_dclock_dlinking_off_revA = [
			29 01 00 00 00 00 03 F0 5A 5A	/* TEST KEY Enable */
			29 01 00 00 00 00 03 79
								00 00
			29 01 00 00 00 00 03 F0 A5 A5	/* TEST KEY Disable */
		];

		/*
		* ************************************************************************************************************************
		* Self Display Operation (DEBUGGING FEATURE)
		* ************************************************************************************************************************
		*/

		samsung,self_display_debug_rx_cmds_revA = [ 06 01 00 00 00 00 01 7F 12 00];	/* read 7F 1st ~ 18th */

		samsung,ldi_error_rx_cmds_revA	= [06 01 00 00 00 00 01 EA 02 00];
#endif
		/* *************************************************************
		 *  FLASH NAND OPERATION & INTERPOLATION(AOR & IRC)
		 * *************************************************************
		 */

		 /*
		 *  Below is common data for interpolation(FLASH and NO FLASH)
		 */

		samsung,normal_brightness = <
			420 412 403 395 387 380 372 365 357 350
			333 316 300 282 265 249 234 220 207 195
			183 172 162 152 143 134 126 119 111 105
			98 93 87 82 77 72 68 64 60 56
			53 50 47 44 41 39 37 34 32 30
			29 27 25 24 22 21 20 19 17 16
			15 14 13 12 11 10
		>;

		samsung,flash_gamma_type = "table";
		samsung,gamma_size = <34>;
		samsung,aor_size = <2>;
		samsung,vint_size = <0>;
		samsung,elvss_size = <3>;
		samsung,irc_size = <0>;
		
		samsung,br_tables {
			vrr60@0 {
				samsung,flash_table_normal_gamma_offset = <0x0000>;
				samsung,flash_table_normal_aor_offset = <0x08C4>;
				samsung,flash_table_normal_vint_offset = <0x0>;
				samsung,flash_table_normal_elvss_offset = <0x0948>;
				samsung,flash_table_normal_irc_offset = <0x00>;

				samsung,flash_table_hmd_gamma_offset = <0x0>;
				samsung,flash_table_hmd_aor_offset = <0x0>;
			};
		};

		/*
		* ************************************************************************************************************************
		* MULTI_RESOLUTION (DSC configs were moved all to below timing set)
		* (C10P does not support MULTI_RESOLUTION, only FHD.)
		* ************************************************************************************************************************
		*/

		qcom,mdss-dsi-display-timings {
			fhd {
				qcom,display-topology = <1 0 1>;
				qcom,default-topology-index = <0>;

				qcom,mdss-dsi-timing-default;

				qcom,mdss-dsi-panel-width = <120>;
				qcom,mdss-dsi-panel-height = <300>;
				qcom,mdss-dsi-t-clk-pre = <0x0F>;
				qcom,mdss-dsi-t-clk-post = <0x13>;

				qcom,mdss-mdp-transfer-time-us = <2866>;
				qcom,mdss-dsi-panel-framerate = <60>;
				qcom,mdss-dsi-panel-clockrate = <384000000>; /* 384Mhz*/
				qcom,mdss-dsi-panel-phy-timings = [00 10 03 03 1C 1E 04 04 02 03 04 00 0F 13];
				qcom,mdss-dsi-h-pulse-width = <80>;
				qcom,mdss-dsi-h-back-porch = <80>;
				qcom,mdss-dsi-h-front-porch = <80>;
				qcom,mdss-dsi-h-sync-skew = <0>;
				qcom,mdss-dsi-v-pulse-width = <80>;
				qcom,mdss-dsi-v-back-porch = <80>;
				qcom,mdss-dsi-v-front-porch = <80>;

				/*qcom,mdss-dsi-timing-switch-command; use samsung,panel_multires_XXX instead*/
				/*qcom,mdss-dsi-timing-switch-command-state;*/
				qcom,mdss-dsi-on-command= [
					29 01 00 00 00 00 03 F0 5A 5A		/* TEST KEY Enable */
					05 01 00 00 14 00 01 11				/* Sleep out, wait 20ms(0x14) */

					/*Common Setting*/
					29 01 00 00 00 00 02 35 00			/* TE Vsync On */

					/*Brightness Control*/
					29 01 00 00 00 00 23 CA				/* 1) Gamma 2.2 Setting */
						07 00 00 00					/* V255 */
						80 80 80			/* V203 R,G,B */
						80 80 80			/* V151 R,G,B */
						80 80 80			/* V87 R,G,B */
						80 80 80			/* V51 R,G,B */
						80 80 80			/* V35 R,G,B */
						80 80 80			/* V23 R,G,B */
						80 80 80			/* V11 R,G,B */
						80 80 80			/*  V7 R,G,B */
						80 80 80			/*  V1 R,G,B */
						00 00 00
					29 01 00 00 00 00 03 B1 00 10		/* AID set : AOR 0% */
					29 01 00 00 00 00 04 B5 19 DC 0A	/* MPS/ELVSS Setting */ /* TBD */
					29 01 00 00 00 00 02 F7 03			/* Gamma, LTPS(AID) update */

					29 01 00 00 00 00 05 2A 00 34 00 AB /* Window update */
					/*29 01 00 00 00 00 05 2B 00 04 01 2B No need PASET */
					29 01 00 00 00 00 03 F0 A5 A5		/* TEST KEY Disable */
				];
				qcom,mdss-dsi-off-command=[
					05 01 00 00 00 00 01 28
					05 01 00 00 78 00 01 10		/* wait 120ms(0x78) */
				];
				qcom,mdss-dsi-on-command-state = "dsi_lp_mode";
				qcom,mdss-dsi-off-command-state = "dsi_hs_mode";
			};
		};
	};
};
